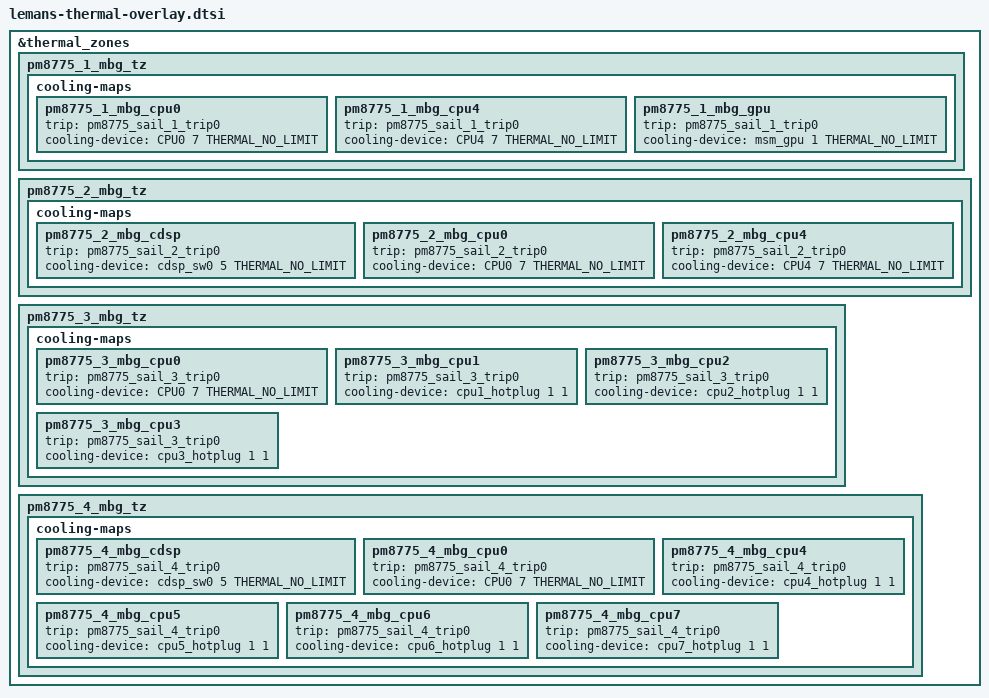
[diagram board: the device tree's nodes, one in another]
#include <dt-bindings/thermal/thermal_qti.h>

&thermal_zones {
	pm8775_1_mbg_tz {
		cooling-maps {
			pm8775_1_mbg_cpu0 {
				trip = <&pm8775_sail_1_trip0>;
				cooling-device = <&CPU0 7 THERMAL_NO_LIMIT>;
			};

			pm8775_1_mbg_cpu4 {
				trip = <&pm8775_sail_1_trip0>;
				cooling-device = <&CPU4 7 THERMAL_NO_LIMIT>;
			};

			pm8775_1_mbg_gpu {
				trip = <&pm8775_sail_1_trip0>;
				cooling-device = <&msm_gpu 1 THERMAL_NO_LIMIT>;
			};
		};
	};

	pm8775_2_mbg_tz {
		cooling-maps {
			pm8775_2_mbg_cdsp {
				trip = <&pm8775_sail_2_trip0>;
				cooling-device = <&cdsp_sw0 5 THERMAL_NO_LIMIT>;
			};

			pm8775_2_mbg_cpu0 {
				trip = <&pm8775_sail_2_trip0>;
				cooling-device = <&CPU0 7 THERMAL_NO_LIMIT>;
			};

			pm8775_2_mbg_cpu4 {
				trip = <&pm8775_sail_2_trip0>;
				cooling-device = <&CPU4 7 THERMAL_NO_LIMIT>;
			};
		};
	};

	pm8775_3_mbg_tz {
		cooling-maps {
			pm8775_3_mbg_cpu0 {
				trip = <&pm8775_sail_3_trip0>;
				cooling-device = <&CPU0 7 THERMAL_NO_LIMIT>;
			};

			pm8775_3_mbg_cpu1 {
				trip = <&pm8775_sail_3_trip0>;
				cooling-device = <&cpu1_hotplug 1 1>;
			};

			pm8775_3_mbg_cpu2 {
				trip = <&pm8775_sail_3_trip0>;
				cooling-device = <&cpu2_hotplug 1 1>;
			};

			pm8775_3_mbg_cpu3 {
				trip = <&pm8775_sail_3_trip0>;
				cooling-device = <&cpu3_hotplug 1 1>;
			};
		};
	};

	pm8775_4_mbg_tz {
		cooling-maps {
			pm8775_4_mbg_cdsp {
				trip = <&pm8775_sail_4_trip0>;
				cooling-device = <&cdsp_sw0 5 THERMAL_NO_LIMIT>;
			};

			pm8775_4_mbg_cpu0 {
				trip = <&pm8775_sail_4_trip0>;
				cooling-device = <&CPU0 7 THERMAL_NO_LIMIT>;
			};

			pm8775_4_mbg_cpu4 {
				trip = <&pm8775_sail_4_trip0>;
				cooling-device = <&cpu4_hotplug 1 1>;
			};

			pm8775_4_mbg_cpu5 {
				trip = <&pm8775_sail_4_trip0>;
				cooling-device = <&cpu5_hotplug 1 1>;
			};

			pm8775_4_mbg_cpu6 {
				trip = <&pm8775_sail_4_trip0>;
				cooling-device = <&cpu6_hotplug 1 1>;
			};

			pm8775_4_mbg_cpu7 {
				trip = <&pm8775_sail_4_trip0>;
				cooling-device = <&cpu7_hotplug 1 1>;
			};
		};
	};
};
